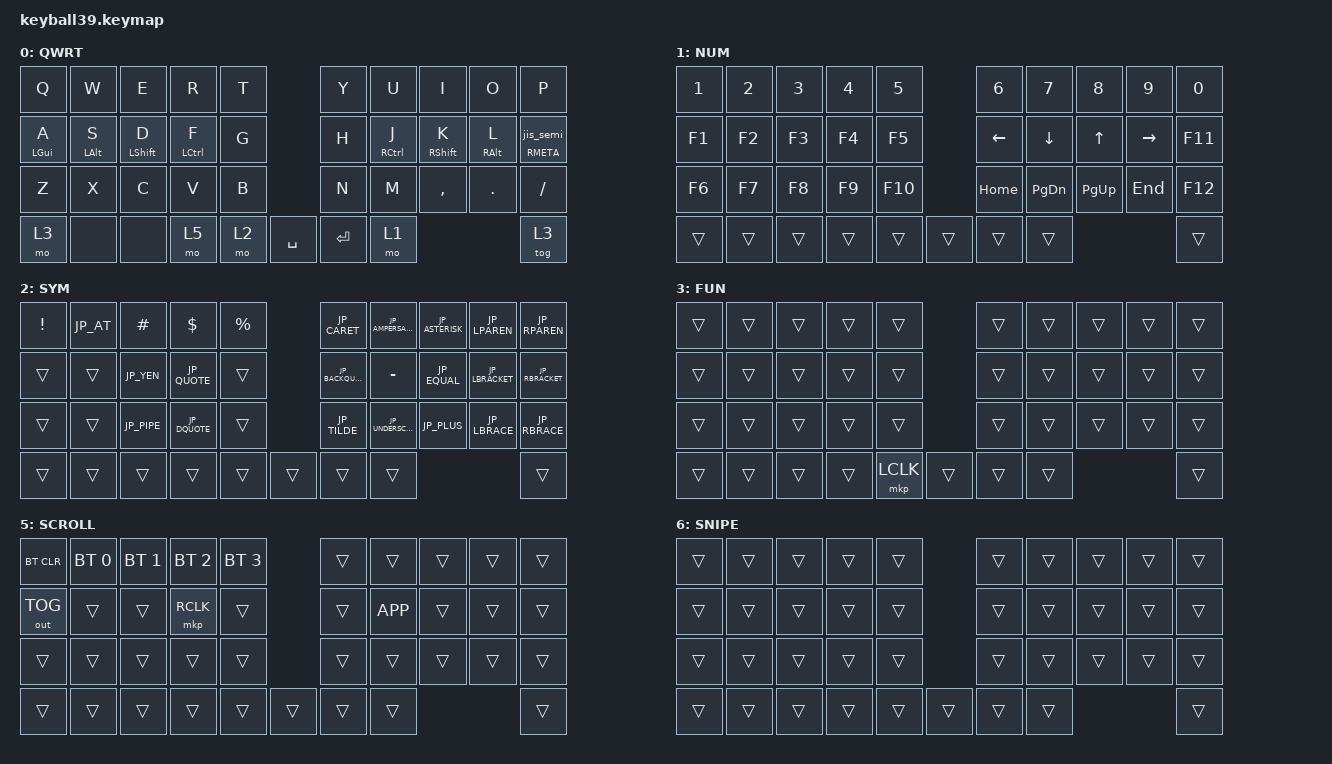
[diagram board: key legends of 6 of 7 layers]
#define DEFAULT 0
#define NUM     1
#define SYM     2
#define FUN     3
#define MOUSE   4
#define SCROLL  5
#define SNIPE   6

#define JP_DQUOTE       AT                // "
#define JP_AMPERSAND    CARET             // &
#define JP_QUOTE        AMPERSAND         // '
#define JP_EQUAL        UNDER             // =
#define JP_CARET        EQUAL             // ^
#define JP_YEN          0x89              // ¥
#define JP_PLUS         COLON             // +
#define JP_TILDE        PLUS              // ~
#define JP_PIPE         LS(INT3)          // |
#define JP_AT           LEFT_BRACKET      // @
#define JP_COLON        SINGLE_QUOTE      // :
#define JP_ASTERISK     DOUBLE_QUOTES     // *
#define JP_BACKQUOTE    LEFT_BRACE        // `
#define JP_UNDERSCORE   LS(INT1)          // _
#define JP_LBRACKET     RIGHT_BRACKET     // [
#define JP_RBRACKET     BACKSLASH         // ]
#define JP_LPAREN       ASTERISK          // (
#define JP_RPAREN       LEFT_PARENTHESIS  // )
#define JP_LBRACE       RIGHT_BRACE       // {
#define JP_RBRACE       PIPE              // }
#define JP_KANA         LANGUAGE_1        // かな
#define JP_EISU         LANGUAGE_2        // 英数
#define JP_HANZEN       GRAVE             // 半角/全角

#define KEYS_L 0 1 2 3 4 10 11 12 13 14 20 21 22 23 24  // Left-hand keys.
#define KEYS_R 5 6 7 8 9 15 16 17 18 19 25 26 27 28 29  // Right-hand keys.
#define KEYS_T 33 34 35 36 37 38                        // Thumb keys.

#define HM_TAPPING_TERM 200
#define HM_TAPPING_TERM_FAST 200
#define HM_PRIOR_IDLE 150

#include <behaviors/mouse_keys.dtsi>
#include <dt-bindings/zmk/mouse.h>
#include <behaviors.dtsi>
#include <dt-bindings/zmk/bt.h>
#include <dt-bindings/zmk/keys.h>
#include <dt-bindings/zmk/outputs.h>

#include "zmk-helpers/helper.h"

// Source desired key-position labels
#include "zmk-helpers/key-labels/glove80.h"

// Source unicode-chars for desired languages
#include "zmk-helpers/unicode-chars/german.dtsi"

//&lt {
//    tapping-term-ms = <240>;
//    flavor = "balanced";
//    quick-tap-ms = <150>;
//};

//&mt {
//    tapping-term-ms = <200>;
//    flavor = "tap-preferred";
//    quick-tap-ms = <150>;
//};

&caps_word { 
    continue-list = <BACKSPACE DELETE MINUS LSHIFT INT1>; 
};

// &sl { release-after-ms = <2000>; };

/ {
    // custom shift using mod-morph 

    behaviors {
        cmqus: comma_question {
            compatible = "zmk,behavior-mod-morph";
            label = "COMMA_QUESTION";
            #binding-cells = <0>;
            bindings = <&kp COMMA>, <&kp QUESTION>;

            mods = <(MOD_LSFT|MOD_RSFT)>;
        };

        dtsmi: dot_semi {
            compatible = "zmk,behavior-mod-morph";
            label = "DOT_SEMI";
            #binding-cells = <0>;
            bindings = <&kp DOT>, <&kp SEMI>;

            mods = <(MOD_LSFT|MOD_RSFT)>;
        };

        //コロンセミコロン
        jis_semi: jis_semi {
            compatible = "zmk,behavior-mod-morph";
            label = "jis_SEMI";
            #binding-cells = <0>;
            bindings = <&kp SEMI>, <&kp SQT>;
            mods = <(MOD_LSFT|MOD_RSFT)>;
            // keep-mods = <(MOD_LSFT|MOD_RSFT)>;
        };

        //mt_semi: mod_tap_jis_semi {
        //    compatible = "zmk,behavior-hold-tap";
        //    label = "MOD_TAP_JIS_SEMI";
        //    flavor = "balanced";
        //    #binding-cells = <2>;
        //    bindings = <&kp>, <&jis_semi>;
        //    tapping-term-ms = <200>;
        //    quick-tap-ms = <175>;
        //    require-prior-idle-ms = <150>;
        //    hold-trigger-key-positions = <Q W E R T A S D F G Z X C V B>;
        //    hold-trigger-on-release;
        //};
        mt_semi: mod_tap_jis_semi {
            compatible = "zmk,behavior-hold-tap";
            label = "MOD_TAP_JIS_SEMI";
            flavor = "balanced";
            #binding-cells = <2>;
            bindings = <&kp>, <&jis_semi>;
            tapping-term-ms = <HM_TAPPING_TERM>;
            //quick-tap-ms = <175>;
            require-prior-idle-ms = <HM_PRIOR_IDLE>;
            hold-trigger-key-positions = <KEYS_L KEYS_T>;
            hold-trigger-on-release;
        };

        mt_lang2: mt_lang2 {
            compatible = "zmk,behavior-hold-tap";
            label = "MOD_TAP_LANGUAGE_2";
            #binding-cells = <2>;
            bindings = <&mo>, <&kp>;
            tapping-term-ms = <200>;
        };

        mt_lang1: mt_lang1 {
            compatible = "zmk,behavior-hold-tap";
            label = "MOD_TAP_LANGUAGE_1";
            #binding-cells = <2>;
            bindings = <&mo>, <&kp>;
            tapping-term-ms = <200>;
        };

        //hml: home_row_mods_left {
        //    compatible = "zmk,behavior-hold-tap";
        //    label = "HOME_ROW_MODS_LEFT";
        //    flavor = "balanced";
        //    #binding-cells = <2>;
        //    bindings = <&kp>, <&kp>;
        //    tapping-term-ms = <200>;
        //    quick-tap-ms = <175>;
        //    require-prior-idle-ms = <150>;
        //    hold-trigger-key-positions = <R Y U I O P H J K L SEMI N M>;
        //    hold-trigger-on-release;
        //};

        //hmr: home_row_mods_right {
        //    compatible = "zmk,behavior-hold-tap";
        //    label = "HOME_ROW_MODS_RIGHT";
        //    flavor = "balanced";
        //    #binding-cells = <2>;
        //    bindings = <&kp>, <&kp>;
        //    tapping-term-ms = <200>;
        //    quick-tap-ms = <175>;
        //    require-prior-idle-ms = <150>;
        //    hold-trigger-key-positions = <Q W E R T A S D F G Z X C V B>;
        //    hold-trigger-on-release;
        //};

        // Positional Homerow mods
        // Homerow mods that prevent accidental activations when rolling keys,
        // such as when typing `st` or `ne` on colemak-dh layouts or `as` on
        // qwerty.
        //
        // Works by only allowing a mod to activate within tapping-term if
        // it's on the opposite side of the keyboard or on the same side thumb
        // keys.

        // Further optimization using urob's timerless homerow mods method:
        // https://github.com/urob/zmk-config#timeless-homerow-mods
        hm_l: homerow_mods_left {
            compatible = "zmk,behavior-hold-tap";
            #binding-cells = <2>;
            bindings = <&kp>,  <&kp>;

            flavor = "balanced";
            tapping-term-ms = <HM_TAPPING_TERM>;
            //quick-tap-ms = <175>;                // repeat on tap-into-hold
            require-prior-idle-ms = <HM_PRIOR_IDLE>;

            hold-trigger-key-positions = <KEYS_R KEYS_T>;
            hold-trigger-on-release;
        };

        hm_r: homerow_mods_right {
            compatible = "zmk,behavior-hold-tap";
            #binding-cells = <2>;
            bindings = <&kp>, <&kp>;

            flavor = "balanced";
            tapping-term-ms = <HM_TAPPING_TERM>;
            //quick-tap-ms = <175>;
            require-prior-idle-ms = <HM_PRIOR_IDLE>;

            hold-trigger-key-positions = <KEYS_L KEYS_T>;
            hold-trigger-on-release;
        };


        // Positional Homerow mods for shift
        // Use faster tapping term and disable some features that may
        // cause false negatives.
        hm_shift_l: hm_shift_l {
            compatible = "zmk,behavior-hold-tap";
            #binding-cells = <2>;
            bindings = <&kp>, <&kp>;

            flavor = "balanced";
            tapping-term-ms = <HM_TAPPING_TERM_FAST>;
            //quick-tap-ms = <175>;
            require-prior-idle-ms = <HM_PRIOR_IDLE>;

            hold-trigger-key-positions = <KEYS_R KEYS_T>;
            // hold-trigger-on-release;
        };

        hm_shift_r: hm_shift_r {
            compatible = "zmk,behavior-hold-tap";
            #binding-cells = <2>;
            bindings = <&kp>, <&kp>;

            flavor = "balanced";
            tapping-term-ms = <HM_TAPPING_TERM_FAST>;
            //quick-tap-ms = <175>;
            require-prior-idle-ms = <HM_PRIOR_IDLE>;

            hold-trigger-key-positions = <KEYS_L KEYS_T>;
            // hold-trigger-on-release;
        };

        /*
         * Non-Positional Homerow Mods
         * Used for &mm_grescm_gui behavior on left hand.
         *
         * Usage: &hm LSHFT T
         * Tap: T
         * Tap-Tap-Hold: Repeat T
         * Hold: LSHIFT
         */
        hm: homerow_mods {
            compatible = "zmk,behavior-hold-tap";
            #binding-cells = <2>;
            bindings = <&kp>, <&kp>;

            flavor = "balanced";
            tapping-term-ms = <HM_TAPPING_TERM>;
            //quick-tap-ms = <200>;
        };

        tog_off: toggle_layer_off {
            compatible = "zmk,behavior-toggle-layer";
            #binding-cells = <1>;
            display-name = "Toggle Layer Off";
            toggle-mode = "off";
        };

        mt_exit_AML_on_tap: mt_exit_AML_on_tap {
            compatible = "zmk,behavior-hold-tap";
            label = "MT_exit_AML_ON_TAP";
            bindings = <&kp>, <&kp_exit_AML>;

            #binding-cells = <2>;
            tapping-term-ms = <200>;
            flavor = "balanced";
            quick-tap-ms = <200>;
        };
    };

    macros {
        Hiragana: Hiragana {
            compatible = "zmk,behavior-macro";
            #binding-cells = <0>;
            bindings = <&kp LC(SPACE)>;
            label = "HIRAGANA";
        };

        exit_AML: exit_AML {
            compatible = "zmk,behavior-macro";
            wait-ms = <0>;
            tap-ms = <0>;
            #binding-cells = <0>;
            bindings = <&tog_off 4>;
            label = "exit_AML";
        };

        kp_exit_AML: kp_exit_AML {
            compatible = "zmk,behavior-macro-one-param";
            wait-ms = <0>;
            tap-ms = <0>;
            #binding-cells = <1>;
            bindings = <&macro_param_1to1 &kp MACRO_PLACEHOLDER &exit_AML>;
            label = "KP_exit_AML";
        };
    };

    combos {
        compatible = "zmk,combos";

        delete {
            bindings = <&kp DELETE>;
            key-positions = <27 28>;
        };

        backspace {
            bindings = <&kp BACKSPACE>;
            key-positions = <7 8>;
        };

        escape {
            bindings = <&kp ESCAPE>;
            key-positions = <21 22>;
        };

        tab {
            bindings = <&kp TAB>;
            key-positions = <2 1>;
        };

        lang1 {
            bindings = <&kp LANGUAGE_1>;
            key-positions = <26 27>;
        };

        lang2 {
            bindings = <&kp LANGUAGE_2>;
            key-positions = <22 23>;
        };

        capsword {
            bindings = <&caps_word>;
            key-positions = <20 29>;
        };
    };

    keymap {
        compatible = "zmk,keymap";

        default_layer {
            label = "QWRT";
            bindings = <
&kp Q       &kp W           &kp E        &kp R        &kp T                        &kp Y  &kp U        &kp I         &kp O            &kp P
&hm_l LGUI A  &hm_l LEFT_ALT S  &hm_l LSHFT D  &hm_l LCTRL F  &kp G                    &kp H  &hm_r RCTRL J  &hm_r RSHIFT K  &hm_r RIGHT_ALT L  &mt_semi RMETA 0
&kp Z       &kp X           &kp C        &kp V        &kp B                        &kp N  &kp M        &kp COMMA     &kp DOT          &kp SLASH
&mo 3       &none           &none        &mo 5        &mo 2 &kp SPACE              &kp ENTER  &mo 1                                   &tog 3
            >;
        };

        number_layer {
            label = "NUM";
            bindings = <
&kp NUMBER_1  &kp NUMBER_2  &kp NUMBER_3  &kp NUMBER_4  &kp NUMBER_5                  &kp NUMBER_6    &kp NUMBER_7   &kp NUMBER_8  &kp NUMBER_9  &kp NUMBER_0
&kp F1        &kp F2        &kp F3        &kp F4        &kp F5                        &kp LEFT_ARROW  &kp DOWN       &kp UP_ARROW  &kp RIGHT     &kp F11
&kp F6        &kp F7        &kp F8        &kp F9        &kp F10                       &kp HOME        &kp PAGE_DOWN  &kp PAGE_UP   &kp END       &kp F12
&trans        &trans        &trans        &trans        &trans        &trans  &trans  &trans                                                      &trans
            >;
        };

        symbol_layer {
            label = "SYM";
            bindings = <
&kp EXCLAMATION  &kp JP_AT     &kp HASH           &kp DOLLAR    &kp PERCENT                  &kp JP_CARET     &kp JP_AMPERSAND  &kp JP_ASTERISK &kp JP_LPAREN    &kp JP_RPAREN
&trans           &trans        &kp JP_YEN         &kp JP_QUOTE  &trans                       &kp JP_BACKQUOTE &kp MINUS         &kp JP_EQUAL    &kp JP_LBRACKET  &kp JP_RBRACKET
&trans           &trans        &kp JP_PIPE        &kp JP_DQUOTE &trans                       &kp JP_TILDE     &kp JP_UNDERSCORE &kp JP_PLUS     &kp JP_LBRACE    &kp JP_RBRACE
&trans           &trans        &trans             &trans        &trans       &trans          &trans   &trans                                                 &trans
            >;
        };

        function_layer {
            label = "FUN";
            bindings = <
&trans  &trans  &trans  &trans  &trans                  &trans  &trans  &trans  &trans  &trans
&trans  &trans  &trans  &trans  &trans                  &trans  &trans  &trans  &trans  &trans
&trans  &trans  &trans  &trans  &trans                  &trans  &trans  &trans  &trans  &trans
&trans  &trans  &trans  &trans  &mkp LCLK &trans        &trans  &trans                          &trans  
            >;
        };
        mouse_layer {
            label = "MOUSE";
            bindings = <
&trans  &trans  &trans  &trans  &trans                  &trans  &trans  &trans  &trans  &trans
&trans  &trans  &trans  &trans  &trans                  &trans  &trans  &trans  &trans  &trans
&trans  &trans  &trans  &trans  &trans                  &trans  &trans  &trans  &trans  &trans
&trans  &trans  &trans  &trans  &trans  &trans  &trans  &trans                          &trans                                  &none
            >;
        };

        scroll_layer {
            label = "SCROLL";
            bindings = <
&bt BT_CLR  &bt BT_SEL 0  &bt BT_SEL 1  &bt BT_SEL 2  &bt BT_SEL 3                   &trans  &trans  &trans  &trans  &trans
&out OUT_TOG  &trans  &trans  &mkp RCLK  &trans                  &trans  &kp K_APP  &trans  &trans  &trans
&trans  &trans  &trans  &trans  &trans                  &trans  &trans  &trans  &trans  &trans
&trans  &trans  &trans  &trans  &trans  &trans  &trans  &trans                          &trans
            >;
        };

        snipe_layer {
            label = "SNIPE";
            bindings = <
&trans  &trans  &trans  &trans  &trans                  &trans  &trans  &trans  &trans  &trans
&trans  &trans  &trans  &trans  &trans                  &trans  &trans  &trans  &trans  &trans
&trans  &trans  &trans  &trans  &trans                  &trans  &trans  &trans  &trans  &trans
&trans  &trans  &trans  &trans  &trans  &trans  &trans  &trans                          &trans
            >;
        };
    };
};
